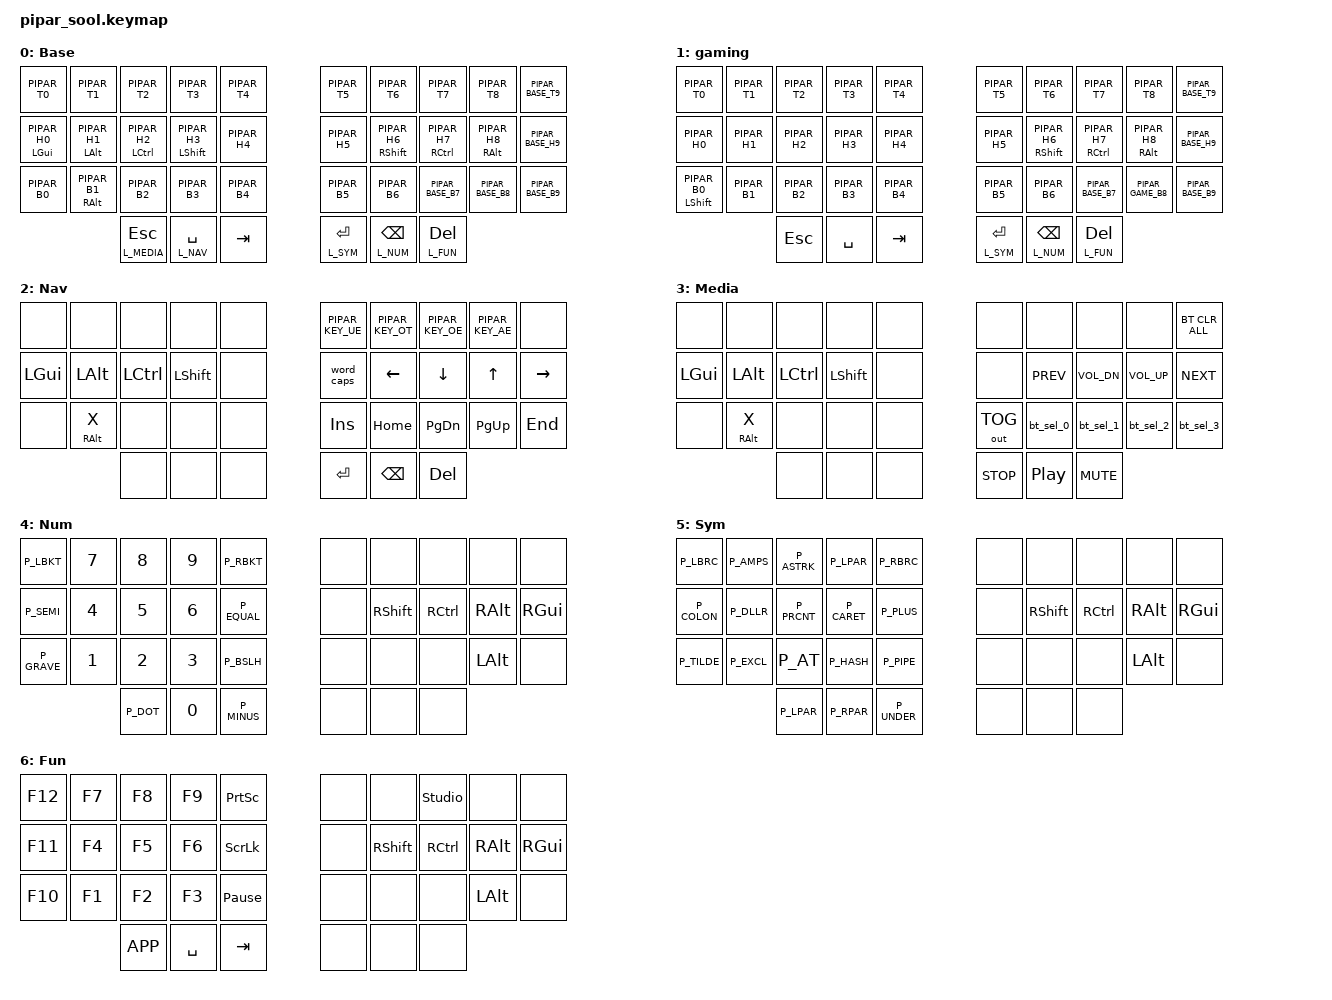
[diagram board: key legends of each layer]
#include <behaviors.dtsi>
#include <dt-bindings/zmk/keys.h>
#include <dt-bindings/zmk/outputs.h>
#include <dt-bindings/zmk/bt.h>
#include <behaviors/unicode.dtsi>
#include <pipar/keymap_variant.h>

/*
 * Pipar ja Sool keymap. Follows the Pipar Point keymap, minus what the Sool
 * doesn't have: the outer pinky column, the trackpoint (Mouse layer) and
 * backlight controls. The Point's Estonian keys (Ü Õ Ö Ä) are on the Nav
 * layer's right-hand top row instead.
 *
 *    00 01 02 03 04       05 06 07 08 09
 *    10 11 12 13 14       15 16 17 18 19
 *    20 21 22 23 24       25 26 27 28 29
 *          30 31 32       33 34 35
 */

#define KEYS_LEFT   0 1 2 3 4 10 11 12 13 14 20 21 22 23 24
#define KEYS_RIGHT  5 6 7 8 9 15 16 17 18 19 25 26 27 28 29
#define KEYS_THUMBS 30 31 32 33 34 35

#include <pipar/estonian.dtsi>

&uc {
    default-mode = <PIPAR_UC_MODE>;
    minimum-length = <PIPAR_UC_MIN_LENGTH>;
    win-compose-key = <RALT>;
};

#define L_BASE      0
#define L_GAMING_DH 1
#define L_NAV       2
#define L_MEDIA     3
#define L_NUM       4
#define L_SYM       5
#define L_FUN       6

/ {

    macros {
        macro_bt_sel_0: macro_bt_sel_0 {
            compatible = "zmk,behavior-macro";
            #binding-cells = <0>;
            wait-ms = <0>;
            bindings = <&bt BT_SEL 0 &bt BT_CLR>;
        };

        macro_bt_sel_1: macro_bt_sel_1 {
            compatible = "zmk,behavior-macro";
            #binding-cells = <0>;
            wait-ms = <0>;
            bindings = <&bt BT_SEL 1 &bt BT_CLR>;
        };

        macro_bt_sel_2: macro_bt_sel_2 {
            compatible = "zmk,behavior-macro";
            #binding-cells = <0>;
            wait-ms = <0>;
            bindings = <&bt BT_SEL 2 &bt BT_CLR>;
        };

        macro_bt_sel_3: macro_bt_sel_3 {
            compatible = "zmk,behavior-macro";
            #binding-cells = <0>;
            wait-ms = <0>;
            bindings = <&bt BT_SEL 3 &bt BT_CLR>;
        };
    };

    combos {
        compatible = "zmk,combos";
        // O + / (right pinky column, home and bottom row)
        combo_gaming_cdh {
            timeout-ms = <50>;
            key-positions = <19 29>;
            bindings = <&to L_GAMING_DH>;
            layers = <L_FUN>;
        };
        combo_base_layer {
            timeout-ms = <50>;
            key-positions = <19 29>;
            bindings = <&to L_BASE>;
            layers = <L_GAMING_DH>;
        };
    };

    behaviors {
        hml: homerow_mods_left {
            compatible = "zmk,behavior-hold-tap";
            #binding-cells = <2>;
            flavor = "balanced";
            require-prior-idle-ms = <150>;
            tapping-term-ms = <280>;
            quick-tap-ms = <175>;
            bindings = <&kp>, <&kp>;
            hold-trigger-key-positions = <KEYS_RIGHT KEYS_THUMBS>;
            hold-trigger-on-release;
        };

        hmr: homerow_mods_right {
            compatible = "zmk,behavior-hold-tap";
            #binding-cells = <2>;
            flavor = "balanced";
            require-prior-idle-ms = <150>;
            tapping-term-ms = <280>;
            quick-tap-ms = <175>;
            bindings = <&kp>, <&kp>;
            hold-trigger-key-positions = <KEYS_LEFT KEYS_THUMBS>;
            hold-trigger-on-release;
        };

        bt_sel_0: bluetooth_select_0 {
            compatible = "zmk,behavior-mod-morph";
            #binding-cells = <0>;
            bindings = <&bt BT_SEL 0>, <&macro_bt_sel_0>;
            mods = <(MOD_LSFT|MOD_RSFT)>;
        };

        bt_sel_1: bluetooth_select_1 {
            compatible = "zmk,behavior-mod-morph";
            #binding-cells = <0>;
            bindings = <&bt BT_SEL 1>, <&macro_bt_sel_1>;
            mods = <(MOD_LSFT|MOD_RSFT)>;
        };

        bt_sel_2: bluetooth_select_2 {
            compatible = "zmk,behavior-mod-morph";
            #binding-cells = <0>;
            bindings = <&bt BT_SEL 2>, <&macro_bt_sel_2>;
            mods = <(MOD_LSFT|MOD_RSFT)>;
        };

        bt_sel_3: bluetooth_select_3 {
            compatible = "zmk,behavior-mod-morph";
            #binding-cells = <0>;
            bindings = <&bt BT_SEL 3>, <&macro_bt_sel_3>;
            mods = <(MOD_LSFT|MOD_RSFT)>;
        };

        word_caps: word_caps {
            compatible = "zmk,behavior-mod-morph";
            #binding-cells = <0>;
            bindings = <&caps_word>, <&kp CAPS>;
            mods = <(MOD_LSFT|MOD_RSFT)>;
        };
    };

    keymap {
        compatible = "zmk,keymap";

        default_layer {
            display-name = "Base";

            // Colemak-DH shown; letters come from pipar/keymap_variant.h
            // |  Q  |  W  |  F  |  P  |  B  |   |  J  |  L   |  U  |  Y  |  '  |
            // |  A  |  R  |  S  |  T  |  G  |   |  M  |  N   |  E  |  I  |  O  |
            // |  Z  |  X  |  C  |  D  |  V  |   |  K  |  H   |  ,  |  .  |  /  |
            //             | ESC | SPC | TAB |   | ENT | BSPC | DEL |
            bindings = <
&kp PIPAR_T0             &kp PIPAR_T1             &kp PIPAR_T2             &kp PIPAR_T3             &kp PIPAR_T4             &kp PIPAR_T5             &kp PIPAR_T6             &kp PIPAR_T7             &kp PIPAR_T8             PIPAR_BASE_T9
&hml LGUI PIPAR_H0       &hml LALT PIPAR_H1       &hml LCTRL PIPAR_H2      &hml LSHFT PIPAR_H3      &kp PIPAR_H4             &kp PIPAR_H5             &hmr RSHFT PIPAR_H6      &hmr RCTRL PIPAR_H7      &hmr RALT PIPAR_H8       PIPAR_BASE_H9
&kp PIPAR_B0             &hml RALT PIPAR_B1       &kp PIPAR_B2             &kp PIPAR_B3             &kp PIPAR_B4             &kp PIPAR_B5             &kp PIPAR_B6             PIPAR_BASE_B7        PIPAR_BASE_B8          PIPAR_BASE_B9
                                    &lt L_MEDIA ESC   &lt L_NAV SPACE   &kp TAB           &lt L_SYM RET     &lt L_NUM BSPC    &lt L_FUN DEL
            >;
        };

        gaming {
            display-name = PIPAR_GAMING_NAME;

            bindings = <
&kp PIPAR_T0             &kp PIPAR_T1             &kp PIPAR_T2             &kp PIPAR_T3             &kp PIPAR_T4             &kp PIPAR_T5             &kp PIPAR_T6             &kp PIPAR_T7             &kp PIPAR_T8             PIPAR_BASE_T9
&kp PIPAR_H0             &kp PIPAR_H1             &kp PIPAR_H2             &kp PIPAR_H3             &kp PIPAR_H4             &kp PIPAR_H5             &hmr RSHFT PIPAR_H6      &hmr RCTRL PIPAR_H7      &hmr RALT PIPAR_H8       PIPAR_BASE_H9
&mt LSHFT PIPAR_B0       &kp PIPAR_B1             &kp PIPAR_B2             &kp PIPAR_B3             &kp PIPAR_B4             &kp PIPAR_B5             &kp PIPAR_B6             PIPAR_BASE_B7        PIPAR_GAME_B8          PIPAR_BASE_B9
                                    &kp ESC           &kp SPACE         &kp TAB           &lt L_SYM RET     &lt L_NUM BSPC    &lt L_FUN DEL
            >;
        };

        navigation {
            display-name = "Nav";

            // Right-hand top row: the Estonian letters Ü Õ Ö Ä.
            bindings = <
&none             &none             &none             &none             &none             PIPAR_KEY_UE      PIPAR_KEY_OT      PIPAR_KEY_OE      PIPAR_KEY_AE      &none
&kp LGUI          &kp LALT          &kp LCTRL         &kp LSHFT         &none             &word_caps        &kp LEFT          &kp DOWN          &kp UP            &kp RIGHT
&none             &hml RALT X       &none             &none             &none             &kp INSERT        &kp HOME          &kp PAGE_DOWN     &kp PAGE_UP       &kp END
                                    &none             &none             &none             &kp RET           &kp BSPC          &kp DEL
            >;
        };

        media {
            display-name = "Media";

            bindings = <
&none             &none             &none             &none             &none             &none             &none             &none             &none             &bt BT_CLR_ALL
&kp LGUI          &kp LALT          &kp LCTRL         &kp LSHFT         &none             &none             &kp C_PREV        &kp C_VOL_DN      &kp C_VOL_UP      &kp C_NEXT
&none             &hml RALT X       &none             &none             &none             &out OUT_TOG      &bt_sel_0         &bt_sel_1         &bt_sel_2         &bt_sel_3
                                    &none             &none             &none             &kp C_STOP        &kp C_PP          &kp C_MUTE
            >;
        };

        num {
            display-name = "Num";

            bindings = <
P_LBKT            &kp N7            &kp N8            &kp N9            P_RBKT            &none             &none             &none             &none             &none
P_SEMI            &kp N4            &kp N5            &kp N6            P_EQUAL           &none             &kp RSHFT         &kp RCTRL         &kp RALT          &kp RGUI
P_GRAVE           &kp N1            &kp N2            &kp N3            P_BSLH            &none             &none             &none             &kp LALT          &none
                                    P_DOT             &kp N0            P_MINUS           &none             &none             &none
            >;
        };

        sym {
            display-name = "Sym";

            bindings = <
P_LBRC            P_AMPS            P_ASTRK           P_LPAR            P_RBRC            &none             &none             &none             &none             &none
P_COLON           P_DLLR            P_PRCNT           P_CARET           P_PLUS            &none             &kp RSHFT         &kp RCTRL         &kp RALT          &kp RGUI
P_TILDE           P_EXCL            P_AT              P_HASH            P_PIPE            &none             &none             &none             &kp LALT          &none
                                    P_LPAR            P_RPAR            P_UNDER           &none             &none             &none
            >;
        };

        fun {
            display-name = "Fun";

            bindings = <
&kp F12           &kp F7            &kp F8            &kp F9            &kp PSCRN         &none             &none             &studio_unlock    &none             &none
&kp F11           &kp F4            &kp F5            &kp F6            &kp SLCK          &none             &kp RSHFT         &kp RCTRL         &kp RALT          &kp RGUI
&kp F10           &kp F1            &kp F2            &kp F3            &kp PAUSE_BREAK   &none             &none             &none             &kp LALT          &none
                                    &kp K_APP         &kp SPACE         &kp TAB           &none             &none             &none
            >;
        };
    };
};
